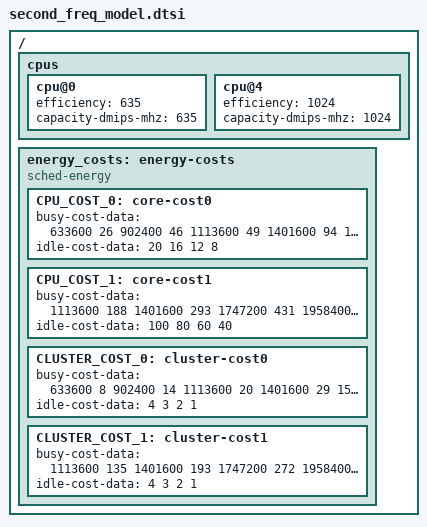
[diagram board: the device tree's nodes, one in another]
/*
 * Auto-generated legacy EAS energy model for incorporation in SoC device tree.
 * Generated by freqbench postprocessing scripts using freqbench results.
 * More info at https://github.com/kdrag0n/freqbench
 */

/ {
	cpus {
		cpu@0 {
			efficiency = <635>;
			capacity-dmips-mhz = <635>;
		};

		cpu@4 {
			efficiency = <1024>;
			capacity-dmips-mhz = <1024>;
		};
	};

	energy_costs: energy-costs {
		compatible = "sched-energy";

		CPU_COST_0: core-cost0 {
			busy-cost-data = <
				  633600   26
				  902400   46
				 1113600   49
				 1401600   94
				 1536000  109
				 1747200  145
				 1843200  176
			>;
			idle-cost-data = <
				20 16 12 8
			>;
		};

		CPU_COST_1: core-cost1 {
			busy-cost-data = <
				 1113600  188
				 1401600  293
				 1747200  431
				 1958400  523
				 2150400  626
				 2208000  733
			>;
			idle-cost-data = <
				100 80 60 40
			>;
		};

		CLUSTER_COST_0: cluster-cost0 {
			busy-cost-data = <
				 633600    8
				 902400   14
				 1113600   20
				 1401600   29
				 1536000   35
				 1747200   49
				 1843200   62
			>;
			idle-cost-data = <
				4 3 2 1
			>;
		};

		CLUSTER_COST_1: cluster-cost1 {
			busy-cost-data = <
				 1113600  135
				 1401600  193
				 1747200  272
				 1958400  363
				 2150400  519
				 2208000  585
			>;
			idle-cost-data = <
				4 3 2 1
			>;
		};
	};
};
